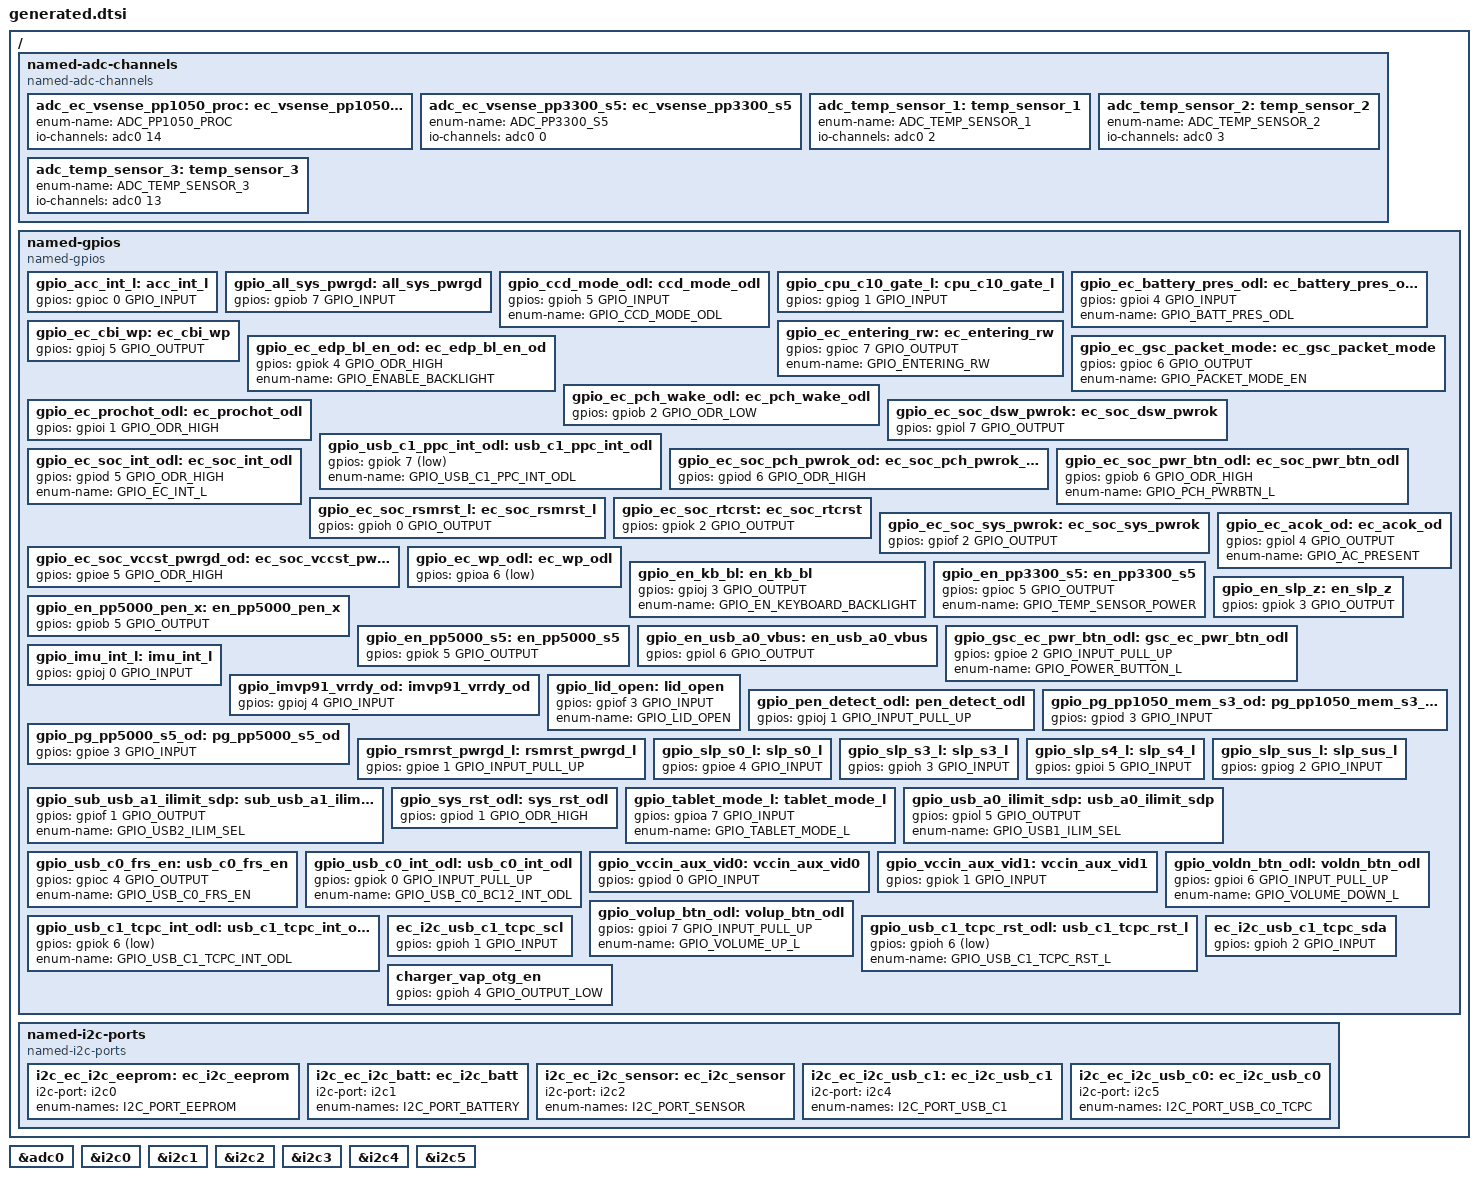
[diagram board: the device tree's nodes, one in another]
/* Copyright 2022 The ChromiumOS Authors
 * Use of this source code is governed by a BSD-style license that can be
 * found in the LICENSE file.
 *
 * This file is auto-generated - do not edit!
 */

/ {

	named-adc-channels {
		compatible = "named-adc-channels";

		adc_ec_vsense_pp1050_proc: ec_vsense_pp1050_proc {
			enum-name = "ADC_PP1050_PROC";
			io-channels = <&adc0 14>;
		};
		adc_ec_vsense_pp3300_s5: ec_vsense_pp3300_s5 {
			enum-name = "ADC_PP3300_S5";
			io-channels = <&adc0 0>;
		};
		adc_temp_sensor_1: temp_sensor_1 {
			enum-name = "ADC_TEMP_SENSOR_1";
			io-channels = <&adc0 2>;
		};
		adc_temp_sensor_2: temp_sensor_2 {
			enum-name = "ADC_TEMP_SENSOR_2";
			io-channels = <&adc0 3>;
		};
		adc_temp_sensor_3: temp_sensor_3 {
			enum-name = "ADC_TEMP_SENSOR_3";
			io-channels = <&adc0 13>;
		};
	};

	named-gpios {
		compatible = "named-gpios";

		gpio_acc_int_l: acc_int_l {
			gpios = <&gpioc 0 GPIO_INPUT>;
		};
		gpio_all_sys_pwrgd: all_sys_pwrgd {
			gpios = <&gpiob 7 GPIO_INPUT>;
		};
		gpio_ccd_mode_odl: ccd_mode_odl {
			gpios = <&gpioh 5 GPIO_INPUT>;
			enum-name = "GPIO_CCD_MODE_ODL";
		};
		gpio_cpu_c10_gate_l: cpu_c10_gate_l {
			gpios = <&gpiog 1 GPIO_INPUT>;
		};
		gpio_ec_battery_pres_odl: ec_battery_pres_odl {
			gpios = <&gpioi 4 GPIO_INPUT>;
			enum-name = "GPIO_BATT_PRES_ODL";
		};
		gpio_ec_cbi_wp: ec_cbi_wp {
			gpios = <&gpioj 5 GPIO_OUTPUT>;
		};
		gpio_ec_edp_bl_en_od: ec_edp_bl_en_od {
			gpios = <&gpiok 4 GPIO_ODR_HIGH>;
			enum-name = "GPIO_ENABLE_BACKLIGHT";
		};
		gpio_ec_entering_rw: ec_entering_rw {
			gpios = <&gpioc 7 GPIO_OUTPUT>;
			enum-name = "GPIO_ENTERING_RW";
		};
		gpio_ec_gsc_packet_mode: ec_gsc_packet_mode {
			gpios = <&gpioc 6 GPIO_OUTPUT>;
			enum-name = "GPIO_PACKET_MODE_EN";
		};
		gpio_ec_pch_wake_odl: ec_pch_wake_odl {
			gpios = <&gpiob 2 GPIO_ODR_LOW>;
		};
		gpio_ec_prochot_odl: ec_prochot_odl {
			gpios = <&gpioi 1 GPIO_ODR_HIGH>;
		};
		gpio_ec_soc_dsw_pwrok: ec_soc_dsw_pwrok {
			gpios = <&gpiol 7 GPIO_OUTPUT>;
		};
		gpio_usb_c1_ppc_int_odl: usb_c1_ppc_int_odl {
			gpios = <&gpiok 7 (GPIO_INPUT | GPIO_ACTIVE_LOW)>;
			enum-name = "GPIO_USB_C1_PPC_INT_ODL";
		};
		gpio_ec_soc_int_odl: ec_soc_int_odl {
			gpios = <&gpiod 5 GPIO_ODR_HIGH>;
			enum-name = "GPIO_EC_INT_L";
		};
		gpio_ec_soc_pch_pwrok_od: ec_soc_pch_pwrok_od {
			gpios = <&gpiod 6 GPIO_ODR_HIGH>;
		};
		gpio_ec_soc_pwr_btn_odl: ec_soc_pwr_btn_odl {
			gpios = <&gpiob 6 GPIO_ODR_HIGH>;
			enum-name = "GPIO_PCH_PWRBTN_L";
		};
		gpio_ec_soc_rsmrst_l: ec_soc_rsmrst_l {
			gpios = <&gpioh 0 GPIO_OUTPUT>;
		};
		gpio_ec_soc_rtcrst: ec_soc_rtcrst {
			gpios = <&gpiok 2 GPIO_OUTPUT>;
		};
		gpio_ec_soc_sys_pwrok: ec_soc_sys_pwrok {
			gpios = <&gpiof 2 GPIO_OUTPUT>;
		};
		gpio_ec_soc_vccst_pwrgd_od: ec_soc_vccst_pwrgd_od {
			gpios = <&gpioe 5 GPIO_ODR_HIGH>;
		};
		gpio_ec_acok_od: ec_acok_od {
			gpios = <&gpiol 4 GPIO_OUTPUT>;
			enum-name = "GPIO_AC_PRESENT";
		};
		gpio_ec_wp_odl: ec_wp_odl {
			gpios = <&gpioa 6 (GPIO_INPUT | GPIO_ACTIVE_LOW)>;
		};
		gpio_en_kb_bl: en_kb_bl {
			gpios = <&gpioj 3 GPIO_OUTPUT>;
			enum-name = "GPIO_EN_KEYBOARD_BACKLIGHT";
		};
		gpio_en_pp3300_s5: en_pp3300_s5 {
			gpios = <&gpioc 5 GPIO_OUTPUT>;
			enum-name = "GPIO_TEMP_SENSOR_POWER";
		};
		gpio_en_pp5000_pen_x: en_pp5000_pen_x {
			gpios = <&gpiob 5 GPIO_OUTPUT>;
		};
		gpio_en_pp5000_s5: en_pp5000_s5 {
			gpios = <&gpiok 5 GPIO_OUTPUT>;
		};
		gpio_en_slp_z: en_slp_z {
			gpios = <&gpiok 3 GPIO_OUTPUT>;
		};
		gpio_en_usb_a0_vbus: en_usb_a0_vbus {
			gpios = <&gpiol 6 GPIO_OUTPUT>;
		};
		gpio_gsc_ec_pwr_btn_odl: gsc_ec_pwr_btn_odl {
			gpios = <&gpioe 2 GPIO_INPUT_PULL_UP>;
			enum-name = "GPIO_POWER_BUTTON_L";
		};
		gpio_imu_int_l: imu_int_l {
			gpios = <&gpioj 0 GPIO_INPUT>;
		};
		gpio_imvp91_vrrdy_od: imvp91_vrrdy_od {
			gpios = <&gpioj 4 GPIO_INPUT>;
		};
		gpio_lid_open: lid_open {
			gpios = <&gpiof 3 GPIO_INPUT>;
			enum-name = "GPIO_LID_OPEN";
		};
		gpio_pen_detect_odl: pen_detect_odl {
			gpios = <&gpioj 1 GPIO_INPUT_PULL_UP>;
		};
		gpio_pg_pp1050_mem_s3_od: pg_pp1050_mem_s3_od {
			gpios = <&gpiod 3 GPIO_INPUT>;
		};
		gpio_pg_pp5000_s5_od: pg_pp5000_s5_od {
			gpios = <&gpioe 3 GPIO_INPUT>;
		};
		gpio_rsmrst_pwrgd_l: rsmrst_pwrgd_l {
			gpios = <&gpioe 1 GPIO_INPUT_PULL_UP>;
		};
		gpio_slp_s0_l: slp_s0_l {
			gpios = <&gpioe 4 GPIO_INPUT>;
		};
		gpio_slp_s3_l: slp_s3_l {
			gpios = <&gpioh 3 GPIO_INPUT>;
		};
		gpio_slp_s4_l: slp_s4_l {
			gpios = <&gpioi 5 GPIO_INPUT>;
		};
		gpio_slp_sus_l: slp_sus_l {
			gpios = <&gpiog 2 GPIO_INPUT>;
		};
		gpio_sub_usb_a1_ilimit_sdp: sub_usb_a1_ilimit_sdp {
			gpios = <&gpiof 1 GPIO_OUTPUT>;
			enum-name = "GPIO_USB2_ILIM_SEL";
		};
		gpio_sys_rst_odl: sys_rst_odl {
			gpios = <&gpiod 1 GPIO_ODR_HIGH>;
		};
		gpio_tablet_mode_l: tablet_mode_l {
			gpios = <&gpioa 7 GPIO_INPUT>;
			enum-name = "GPIO_TABLET_MODE_L";
		};
		gpio_usb_a0_ilimit_sdp: usb_a0_ilimit_sdp {
			gpios = <&gpiol 5 GPIO_OUTPUT>;
			enum-name = "GPIO_USB1_ILIM_SEL";
		};
		gpio_usb_c0_frs_en: usb_c0_frs_en {
			gpios = <&gpioc 4 GPIO_OUTPUT>;
			enum-name = "GPIO_USB_C0_FRS_EN";
		};
		gpio_usb_c0_int_odl: usb_c0_int_odl {
			gpios = <&gpiok 0 GPIO_INPUT_PULL_UP>;
			enum-name = "GPIO_USB_C0_BC12_INT_ODL";
		};
		gpio_vccin_aux_vid0: vccin_aux_vid0 {
			gpios = <&gpiod 0 GPIO_INPUT>;
		};
		gpio_vccin_aux_vid1: vccin_aux_vid1 {
			gpios = <&gpiok 1 GPIO_INPUT>;
		};
		gpio_voldn_btn_odl: voldn_btn_odl {
			gpios = <&gpioi 6 GPIO_INPUT_PULL_UP>;
			enum-name = "GPIO_VOLUME_DOWN_L";
		};
		gpio_volup_btn_odl: volup_btn_odl {
			gpios = <&gpioi 7 GPIO_INPUT_PULL_UP>;
			enum-name = "GPIO_VOLUME_UP_L";
		};
		gpio_usb_c1_tcpc_int_odl: usb_c1_tcpc_int_odl {
			gpios = <&gpiok 6 (GPIO_INPUT | GPIO_ACTIVE_LOW)>;
			enum-name = "GPIO_USB_C1_TCPC_INT_ODL";
		};
		gpio_usb_c1_tcpc_rst_odl: usb_c1_tcpc_rst_l {
			gpios = <&gpioh 6 (GPIO_ODR_HIGH | GPIO_ACTIVE_LOW)>;
			enum-name = "GPIO_USB_C1_TCPC_RST_L";
		};
		ec_i2c_usb_c1_tcpc_scl {
			gpios = <&gpioh 1 GPIO_INPUT>;
		};
		ec_i2c_usb_c1_tcpc_sda {
			gpios = <&gpioh 2 GPIO_INPUT>;
		};
		charger_vap_otg_en {
			gpios = <&gpioh 4 GPIO_OUTPUT_LOW>;
		};
	};

	named-i2c-ports {
		compatible = "named-i2c-ports";

		i2c_ec_i2c_eeprom: ec_i2c_eeprom {
			i2c-port = <&i2c0>;
			enum-names = "I2C_PORT_EEPROM";
		};
		i2c_ec_i2c_batt: ec_i2c_batt {
			i2c-port = <&i2c1>;
			enum-names = "I2C_PORT_BATTERY";
		};
		i2c_ec_i2c_sensor: ec_i2c_sensor {
			i2c-port = <&i2c2>;
			enum-names = "I2C_PORT_SENSOR";
		};
		i2c_ec_i2c_usb_c1: ec_i2c_usb_c1 {
			i2c-port = <&i2c4>;
			enum-names = "I2C_PORT_USB_C1";
		};
		i2c_ec_i2c_usb_c0: ec_i2c_usb_c0 {
			i2c-port = <&i2c5>;
			enum-names = "I2C_PORT_USB_C0_TCPC";
		};
	};
};

&adc0 {
	status = "okay";
};

&i2c0 {
	status = "okay";
};

&i2c1 {
	status = "okay";
};

&i2c2 {
	status = "okay";
};

&i2c3 {
	status = "okay";
};

&i2c4 {
	status = "okay";
};

&i2c5 {
	status = "okay";
};

